# STM32F107xC register map
File version: 1.0
Registers are 32-bit, read-write, reset 0x0 unless marked. A register's access mark holds for its fields unless they carry their own. Offsets are from the block's base; [hi:lo] are bit positions; {n}, {i} and the like mark numbered series; 'fields as' and 'values as' point back to an identical list.

## AFIO — Alternate Function I/O
Base 0x40010000
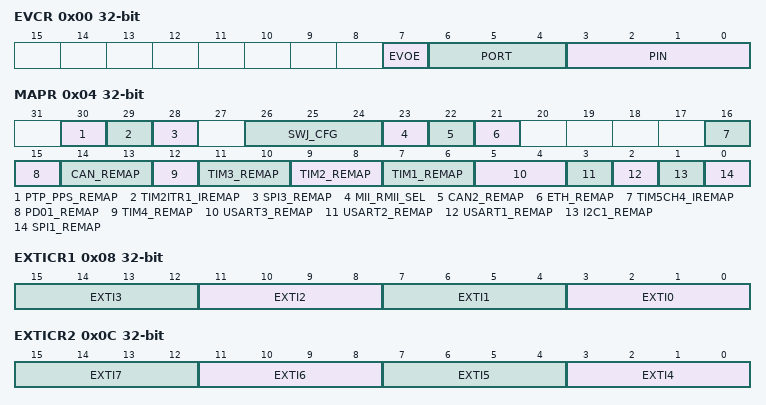
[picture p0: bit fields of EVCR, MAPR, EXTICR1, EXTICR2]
0x00 EVCR
  [7] EVOE — Event Output Enable
  [6:4] PORT — PORT[2:0] bits (Port selection)
  [3:0] PIN — PIN[3:0] bits (Pin selection)
0x04 MAPR
  [30] PTP_PPS_REMAP — PTP_PPS_REMAP bit (Ethernet PTP PPS remapping)
  [29] TIM2ITR1_IREMAP — TIM2ITR1_IREMAP bit (TIM2 internal trigger 1 remapping)
  [28] SPI3_REMAP — SPI3_REMAP bit (SPI3 remapping)
  [26:24] SWJ_CFG — SWJ_CFG[2:0] bits (Serial Wire JTAG configuration)
  [23] MII_RMII_SEL — MII_RMII_SEL bit (Ethernet MII or RMII selection)
  [22] CAN2_REMAP — CAN2_REMAP bit (CAN2 I/O remapping)
  [21] ETH_REMAP — SPI3_REMAP bit (Ethernet MAC I/O remapping)
  [16] TIM5CH4_IREMAP — TIM5 Channel4 Internal Remap
  [15] PD01_REMAP — Port D0/Port D1 mapping on OSC_IN/OSC_OUT
  [14:13] CAN_REMAP — CAN_REMAP[1:0] bits (CAN Alternate function remapping)
  [12] TIM4_REMAP — TIM4_REMAP bit (TIM4 remapping)
  [11:10] TIM3_REMAP — TIM3_REMAP[1:0] bits (TIM3 remapping)
  [9:8] TIM2_REMAP — TIM2_REMAP[1:0] bits (TIM2 remapping)
  [7:6] TIM1_REMAP — TIM1_REMAP[1:0] bits (TIM1 remapping)
  [5:4] USART3_REMAP — USART3_REMAP[1:0] bits (USART3 remapping)
  [3] USART2_REMAP — USART2 remapping
  [2] USART1_REMAP — USART1 remapping
  [1] I2C1_REMAP — I2C1 remapping
  [0] SPI1_REMAP — SPI1 remapping
0x08 EXTICR1
  [4n+3:4n] EXTI{n} (n=0..3) — EXTI {n} configuration
0x0C EXTICR2
  [4n-13:4n-16] EXTI{n} (n=4..7) — EXTI {n} configuration
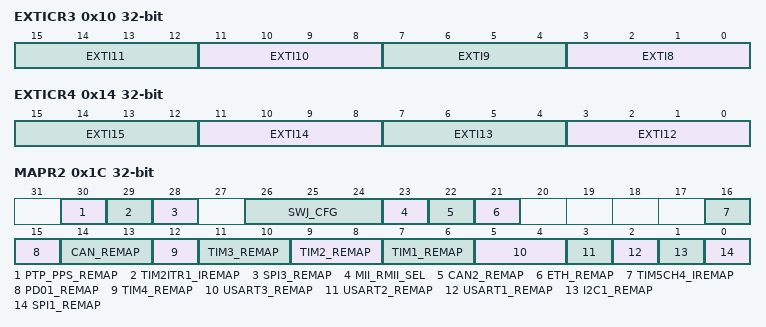
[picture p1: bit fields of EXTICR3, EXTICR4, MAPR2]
0x10 EXTICR3
  [4n-29:4n-32] EXTI{n} (n=8..11) — EXTI {n} configuration
0x14 EXTICR4
  [4n-45:4n-48] EXTI{n} (n=12..15) — EXTI {n} configuration
0x1C MAPR2
  fields as MAPR

## EXTI — External Interrupt/Event Controller
Base 0x40010400
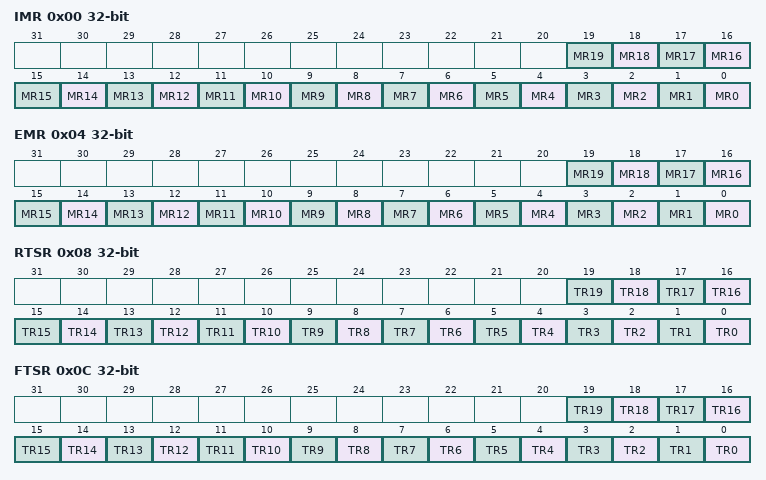
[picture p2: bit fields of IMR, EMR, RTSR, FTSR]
0x00 IMR
  [n] MR{n} (n=0..19) — Interrupt Mask on line {n}
0x04 EMR
  [n] MR{n} (n=0..19) — Event Mask on line {n}
0x08 RTSR
  [n] TR{n} (n=0..19) — Rising trigger event configuration bit of line {n}
0x0C FTSR
  [n] TR{n} (n=0..19) — Falling trigger event configuration bit of line {n}
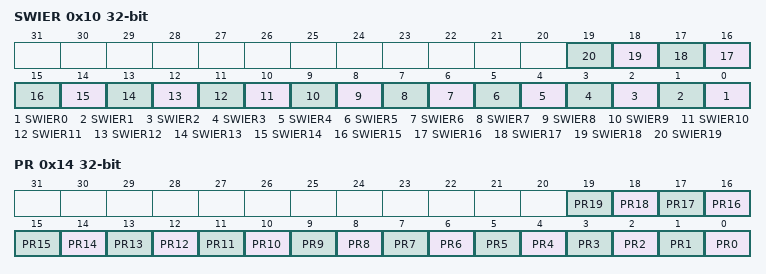
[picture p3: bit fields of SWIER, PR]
0x10 SWIER
  [n] SWIER{n} (n=0..19) — Software Interrupt on line {n}
0x14 PR
  [n] PR{n} (n=0..19) — Pending bit for line {n}

## GPIOA — General Purpose I/O
Base 0x40010800
Same registers: GPIOB 0x40010C00, GPIOC 0x40011000, GPIOD 0x40011400, GPIOE 0x40011800
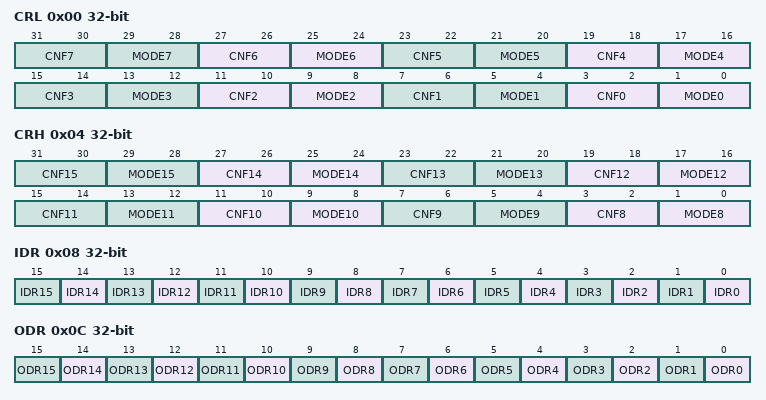
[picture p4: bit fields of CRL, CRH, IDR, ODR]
0x00 CRL
  [4n+3:4n+2] CNF{n} (n=0..7) — CNF{n}[1:0] bits (Port x configuration bits, pin {n})
  [4n+1:4n] MODE{n} (n=0..7) — MODE{n}[1:0] bits (Port x mode bits, pin {n})
0x04 CRH
  [4n-29:4n-30] CNF{n} (n=8..15) — CNF{n}[1:0] bits (Port x configuration bits, pin {n})
  [4n-31:4n-32] MODE{n} (n=8..15) — MODE{n}[1:0] bits (Port x mode bits, pin {n})
0x08 IDR
  [n] IDR{n} (n=0..15) — Port input data, bit {n}
0x0C ODR
  [n] ODR{n} (n=0..15) — Port output data, bit {n}
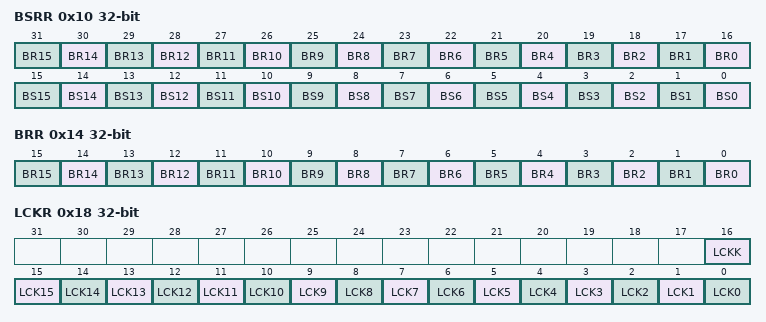
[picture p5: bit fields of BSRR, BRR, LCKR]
0x10 BSRR
  [n+16] BR{n} (n=0..15) — Port x Reset bit {n}
  [n] BS{n} (n=0..15) — Port x Set bit {n}
0x14 BRR
  [n] BR{n} (n=0..15) — Port x Reset bit {n}
0x18 LCKR
  [16] LCKK — Lock key
  [n] LCK{n} (n=0..15) — Port x Lock bit {n}

## DMA1
Base 0x40020000
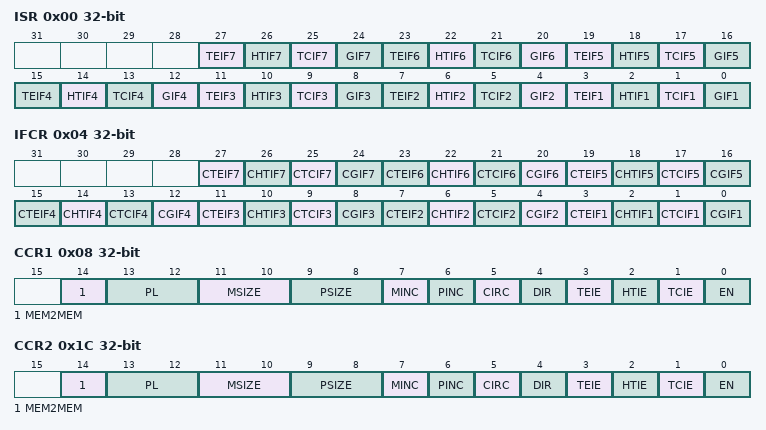
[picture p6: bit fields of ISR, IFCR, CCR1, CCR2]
0x00 ISR
  [4n-1] TEIF{n} (n=1..7) — Channel {n} Transfer Error flag
  [4n-2] HTIF{n} (n=1..7) — Channel {n} Half Transfer flag
  [4n-3] TCIF{n} (n=1..7) — Channel {n} Transfer Complete flag
  [4n-4] GIF{n} (n=1..7) — Channel {n} Global interrupt flag
0x04 IFCR
  [4n-1] CTEIF{n} (n=1..7) — Channel {n} Transfer Error clear
  [4n-2] CHTIF{n} (n=1..7) — Channel {n} Half Transfer clear
  [4n-3] CTCIF{n} (n=1..7) — Channel {n} Transfer Complete clear
  [4n-4] CGIF{n} (n=1..7) — Channel {n} Global interrupt clear
0x08 CCR1
  [14] MEM2MEM — Memory to memory mode
  [13:12] PL — PL[1:0] bits(Channel Priority level)
  [11:10] MSIZE — MSIZE[1:0] bits (Memory size)
  [9:8] PSIZE — PSIZE[1:0] bits (Peripheral size)
  [7] MINC — Memory increment mode
  [6] PINC — Peripheral increment mode
  [5] CIRC — Circular mode
  [4] DIR — Data transfer direction
  [3] TEIE — Transfer error interrupt enable
  [2] HTIE — Half Transfer interrupt enable
  [1] TCIE — Transfer complete interrupt enable
  [0] EN — Channel enable
0x0C CNDTR1
  [15:0] NDT — Number of data to Transfer
0x10 CPAR1
  [31:0] PA — Peripheral Address
{0x0+0x14*i} CMAR{i} (i=1..7)
  [31:0] MA — Memory Address
0x1C CCR2
  fields as CCR1
0x20 CNDTR2
  [15:0] NDT — Number of data to Transfer
0x24 CPAR2
  [31:0] PA — Peripheral Address
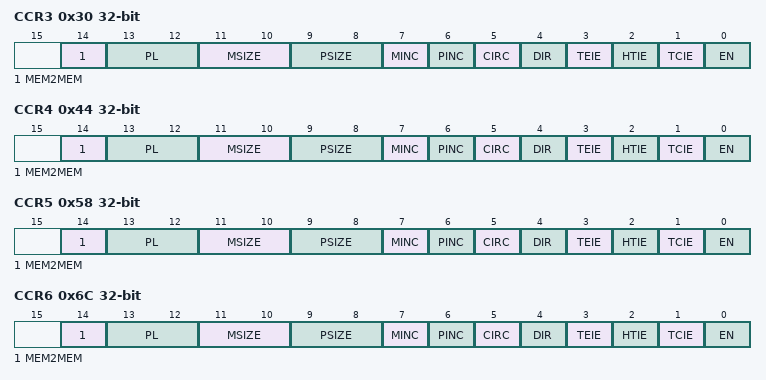
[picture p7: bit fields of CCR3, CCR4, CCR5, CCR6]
0x30 CCR3
  fields as CCR1
0x34 CNDTR3
  [15:0] NDT — Number of data to Transfer
0x38 CPAR3
  [31:0] PA — Peripheral Address
0x44 CCR4
  fields as CCR1
0x48 CNDTR4
  [15:0] NDT — Number of data to Transfer
0x4C CPAR4
  [31:0] PA — Peripheral Address
0x58 CCR5
  fields as CCR1
0x5C CNDTR5
  [15:0] NDT — Number of data to Transfer
0x60 CPAR5
  [31:0] PA — Peripheral Address
0x6C CCR6
  fields as CCR1
0x70 CNDTR6
  [15:0] NDT — Number of data to Transfer
0x74 CPAR6
  [31:0] PA — Peripheral Address
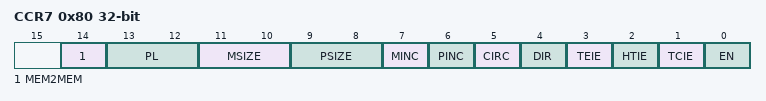
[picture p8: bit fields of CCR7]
0x80 CCR7
  fields as CCR1
0x84 CNDTR7
  [15:0] NDT — Number of data to Transfer
0x88 CPAR7
  [31:0] PA — Peripheral Address

## DMA2
Base 0x40020400
Registers as DMA1, without CCR6, CNDTR6, CPAR6, CMAR6, CCR7, CNDTR7, CPAR7, CMAR7.
